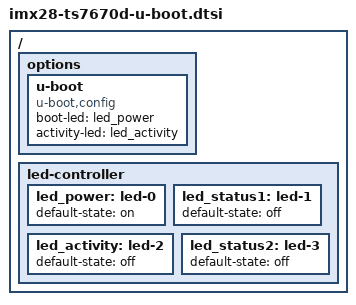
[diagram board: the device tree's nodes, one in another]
// SPDX-License-Identifier: GPL-2.0+
/*
 * Copyright 2019
 * Lukasz Majewski, DENX Software Engineering, lukma@denx.de
 *
 * SPDX-License-Identifier:     GPL-2.0+ or X11
 */

#include "imx28-u-boot.dtsi"

/ {
	options {
		u-boot {
			compatible = "u-boot,config";
			boot-led = <&led_power>;
			activity-led = <&led_activity>;
		};
	};

	led-controller {
		led_power: led-0 {
			default-state = "on";
		};

		led_status1: led-1 {
			default-state = "off";
		};

		led_activity: led-2 {
			default-state = "off";
		};

		led_status2: led-3 {
			default-state = "off";
		};
	};
};
